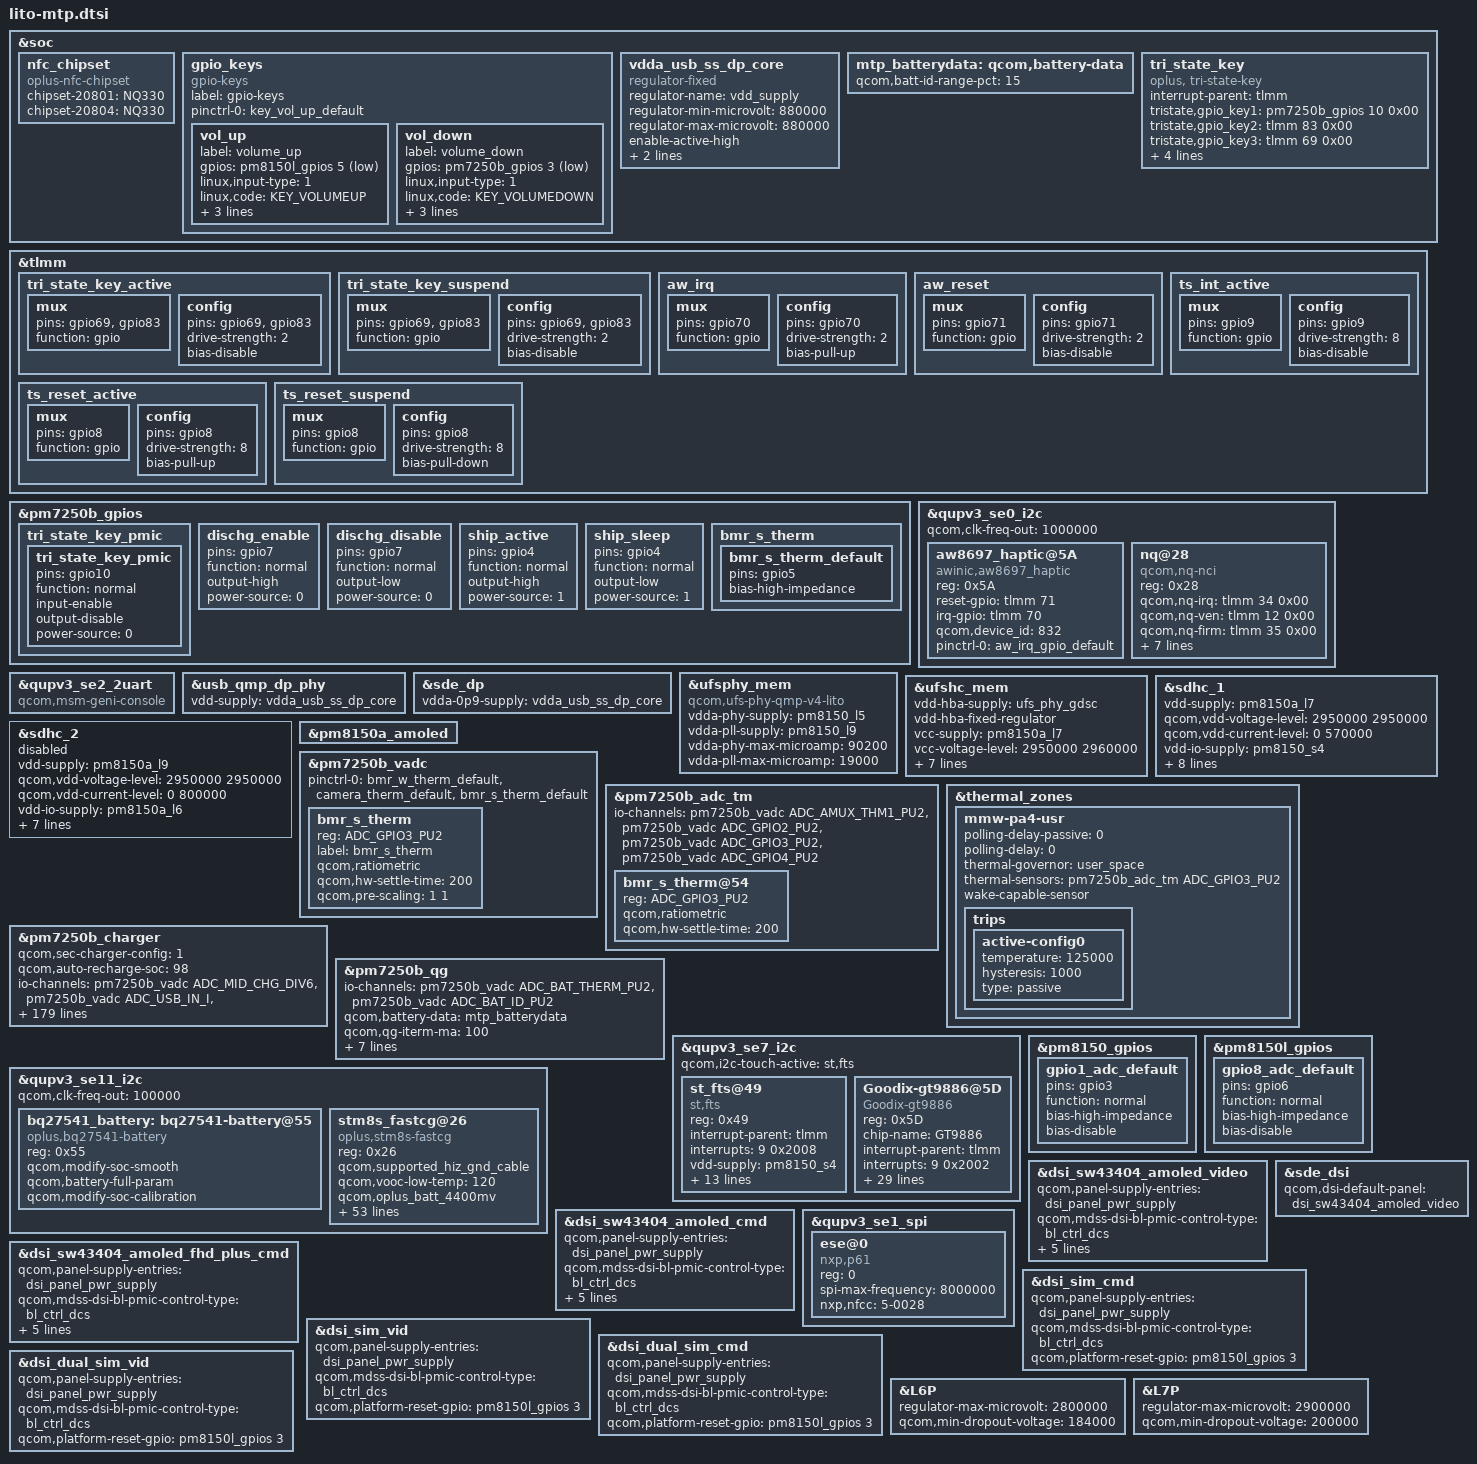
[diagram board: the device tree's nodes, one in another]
#include <dt-bindings/gpio/gpio.h>
#include "lito-audio-overlay.dtsi"
#include "lito-pmic-overlay.dtsi"
#include "lito-sde-display.dtsi"
#include "lito-thermal-overlay.dtsi"
#include "lito-20801-sensor.dtsi"

&soc {
    //add for nfc_chipset
	nfc_chipset {
		compatible = "oplus-nfc-chipset";
		chipset-20801 = "NQ330";
		chipset-20804 = "NQ330";
	};
	gpio_keys {
		compatible = "gpio-keys";
		label = "gpio-keys";

		pinctrl-names = "default";
		pinctrl-0 = <&key_vol_up_default>;

		vol_up {
			label = "volume_up";
			gpios = <&pm8150l_gpios 5 GPIO_ACTIVE_LOW>;
			linux,input-type = <1>;
			linux,code = <KEY_VOLUMEUP>;
			gpio-key,wakeup;
			debounce-interval = <15>;
			linux,can-disable;
		};

               vol_down {
                        label = "volume_down";
                        gpios = <&pm7250b_gpios  3 GPIO_ACTIVE_LOW>;
                        linux,input-type = <1>;
                        linux,code = <KEY_VOLUMEDOWN>;
                        gpio-key,wakeup;
                        debounce-interval = <15>;
                        linux,can-disable;
                };

	};

	vdda_usb_ss_dp_core: vdda_usb_ss_dp_core {
		compatible = "regulator-fixed";
		regulator-name = "vdd_supply";
		regulator-min-microvolt = <880000>;
		regulator-max-microvolt = <880000>;
		enable-active-high;
		gpio = <&pm8150l_gpios 12 GPIO_ACTIVE_HIGH>;
		pinctrl-names = "default";
		pinctrl-0 = <&usb_eldo13>;
	};

	mtp_batterydata: qcom,battery-data {
		qcom,batt-id-range-pct = <15>;
		#include "qg-batterydata-alium-3600mah.dtsi"
		#include "qg-batterydata-atl466271_3300mAh.dtsi"
	};
	
	tri_state_key:tri_state_key {
		compatible = "oplus, tri-state-key";
		status = "ok";
		interrupt-parent = <&tlmm>;
		tristate,gpio_key1 = <&pm7250b_gpios 10 0x00>;
		tristate,gpio_key2 = <&tlmm 83 0x00>;
		tristate,gpio_key3 = <&tlmm 69 0x00>;
		pinctrl-names =
					"pmx_tri_state_key_active",
					"pmx_tri_state_key_suspend";
		pinctrl-0 = <&tri_state_key_active &tri_state_key_pmic>;
		pinctrl-1 = <&tri_state_key_suspend &tri_state_key_pmic>;
	};
};


&tlmm{
	tri_state_key_active: tri_state_key_active {
		mux {
			pins = "gpio69", "gpio83";
			function = "gpio";
		};
		config {
			pins = "gpio69", "gpio83";
			drive-strength = <2>;
			bias-disable;
		};
	};

	tri_state_key_suspend: tri_state_key_suspend {
		mux {
			pins = "gpio69", "gpio83";
			function = "gpio";
		};
		config {
			pins = "gpio69", "gpio83";
			drive-strength = <2>;
			bias-disable;
		};
	};
};

&pm7250b_gpios {
	tri_state_key_pmic {
		tri_state_key_pmic: tri_state_key_pmic {
			pins = "gpio10";
			function = "normal";
			input-enable;
			output-disable;
			power-source = <0>;
		};
	};

        dischg_enable: dischg_enable {
                        pins = "gpio7";
                        function = "normal";
                        output-high;
                        power-source = <0>;
        };

        dischg_disable: dischg_disable {
                        pins = "gpio7";
                        function = "normal";
                        output-low;
                        power-source = <0>;
        };

        ship_active: ship_active {
                        pins = "gpio4";
                        function = "normal";
                        output-high;
                        power-source = <1>;     /* 1.8V input supply */
        };

        ship_sleep: ship_sleep {
                        pins = "gpio4";
                        function = "normal";
                        output-low;
                        power-source = <1>;     /* 1.8V input supply */
        };
};


/*for aw haptic start*/

&tlmm {
       aw_irq: aw_irq {
       mux {
            pins = "gpio70";
            function = "gpio";
       };
       config {
               pins = "gpio70";
               drive-strength = <2>;
               bias-pull-up;
       };
    };
    aw_reset: aw_reset {
       mux {
	            pins = "gpio71";
	            function = "gpio";
	       };
	      config {
	              pins = "gpio71";
	              drive-strength = <2>;
	              bias-disable;
	      };
      };
};
&qupv3_se0_i2c {
	status = "ok";
	aw8697_haptic@5A {
		compatible = "awinic,aw8697_haptic";
		reg = <0x5A>;
		reset-gpio = <&tlmm 71 0x00>;
		irq-gpio = <&tlmm 70 0x00>;
		pinctrl-names = "default";
		qcom,device_id = <832>;

		pinctrl-0 = <&aw_irq_gpio_default>;
		status = "okay";
	};
};

&qupv3_se2_2uart {
    compatible = "qcom,msm-geni-console";
};

&usb_qmp_dp_phy {
	vdd-supply = <&vdda_usb_ss_dp_core>;
};

&sde_dp {
	vdda-0p9-supply = <&vdda_usb_ss_dp_core>;
};

&ufsphy_mem {
	compatible = "qcom,ufs-phy-qmp-v4-lito";

	vdda-phy-supply = <&pm8150_l5>;
	vdda-pll-supply = <&pm8150_l9>;
	vdda-phy-max-microamp = <90200>;
	vdda-pll-max-microamp = <19000>;

	status = "ok";
};

&ufshc_mem {
	vdd-hba-supply = <&ufs_phy_gdsc>;
	vdd-hba-fixed-regulator;
	vcc-supply = <&pm8150a_l7>;
	vcc-voltage-level = <2950000 2960000>;
	vccq2-supply = <&pm8150_s4>;
	vcc-max-microamp = <800000>;
	vccq2-max-microamp = <800000>;

	qcom,vddp-ref-clk-supply = <&pm8150_l9>;
	qcom,vddp-ref-clk-max-microamp = <100>;
	qcom,vddp-ref-clk-min-uV = <1152000>;
	qcom,vddp-ref-clk-max-uV = <1200000>;
	status = "ok";
};

&sdhc_1 {
	vdd-supply = <&pm8150a_l7>;
	qcom,vdd-voltage-level = <2950000 2950000>;
	qcom,vdd-current-level = <0 570000>;

	vdd-io-supply = <&pm8150_s4>;
	qcom,vdd-io-always-on;
	qcom,vdd-io-lpm-sup;
	qcom,vdd-io-voltage-level = <1800000 1800000>;
	qcom,vdd-io-current-level = <0 325000>;

	pinctrl-names = "active", "sleep";
	pinctrl-0 = <&sdc1_clk_on &sdc1_cmd_on &sdc1_data_on
					&sdc1_rclk_on>;
	pinctrl-1 = <&sdc1_clk_off &sdc1_cmd_off &sdc1_data_off
					&sdc1_rclk_off>;

	status = "ok";
};

&sdhc_2 {
	vdd-supply = <&pm8150a_l9>;
	qcom,vdd-voltage-level = <2950000 2950000>;
	qcom,vdd-current-level = <0 800000>;

	vdd-io-supply = <&pm8150a_l6>;
	qcom,vdd-io-voltage-level = <1800000 2950000>;
	qcom,vdd-io-current-level = <0 22000>;

	pinctrl-names = "active", "sleep";
	pinctrl-0 = <&sdc2_clk_on  &sdc2_cmd_on &sdc2_data_on &sdc2_cd_on>;
	pinctrl-1 = <&sdc2_clk_off &sdc2_cmd_off &sdc2_data_off &sdc2_cd_off>;

	cd-gpios = <&tlmm 69 GPIO_ACTIVE_LOW>;

	status = "disabled";
};

&pm8150a_amoled {
	status = "ok";
};

&pm7250b_vadc {
	pinctrl-0 = <
		&bmr_w_therm_default
		&camera_therm_default
		&bmr_s_therm_default
	>;

	bmr_s_therm {
		reg = <ADC_GPIO3_PU2>;
		label = "bmr_s_therm";
		qcom,ratiometric;
		qcom,hw-settle-time = <200>;
		qcom,pre-scaling = <1 1>;
	};
};

&pm7250b_gpios {
	bmr_s_therm {
		bmr_s_therm_default: bmr_s_therm_default {
			pins = "gpio5";
			bias-high-impedance;
		};
	};
};

&pm7250b_adc_tm {
	io-channels = <&pm7250b_vadc ADC_AMUX_THM1_PU2>,
			<&pm7250b_vadc ADC_GPIO2_PU2>,
			<&pm7250b_vadc ADC_GPIO3_PU2>,
			<&pm7250b_vadc ADC_GPIO4_PU2>;

	bmr_s_therm@54 {
		reg = <ADC_GPIO3_PU2>;
		qcom,ratiometric;
		qcom,hw-settle-time = <200>;
	};
};

&thermal_zones {
	mmw-pa4-usr {
		polling-delay-passive = <0>;
		polling-delay = <0>;
		thermal-governor = "user_space";
		thermal-sensors = <&pm7250b_adc_tm ADC_GPIO3_PU2>;
		wake-capable-sensor;
		trips {
			active-config0 {
				temperature = <125000>;
				hysteresis = <1000>;
				type = "passive";
			};
		};
	};
};

&pm7250b_charger {
        status = "ok";
        qcom,sec-charger-config = <1>;
        qcom,auto-recharge-soc = <98>;
        io-channels = <&pm7250b_vadc ADC_MID_CHG_DIV6>,
                      <&pm7250b_vadc ADC_USB_IN_I>,
                      <&pm7250b_vadc ADC_SBUx>,
                      <&pm7250b_vadc ADC_VPH_PWR>,
		      <&pm7250b_vadc ADC_CHG_TEMP>,
		      <&pm7250b_vadc ADC_DIE_TEMP>,
		      <&pm7250b_vadc ADC_AMUX_THM3_PU2>,
                      <&pm7250b_vadc ADC_USB_IN_V_16>,
		      <&pm8150l_vadc ADC_GPIO3_PU2>,
 		      <&pm8150_vadc ADC_GPIO1_PU1>,
 		      <&pm8150l_vadc ADC_GPIO2_PU1>;

        io-channel-names = "mid_voltage",
                           "usb_in_current",
                           "sbux_res",
                           "vph_voltage",
                           "chg_temp",
                           "die_temp",
                           "conn_temp",
                           "usb_in_voltage",
			   "skin_therm",
                           "usb_temp_l",
                           "usb_temp_r";

        qcom,battery-data = <&mtp_batterydata>;
        //qcom,step-charging-enable;
        //qcom,sw-jeita-enable;
        //qcom,wd-bark-time-secs = <16>;
        //qcom,suspend-input-on-debug-batt;
        //qcom,fcc-stepping-enable;
        qcom,smb-internal-pull-kohm = <0>;
        op,low-voltage-charger;
};



/*&pm7250b_charger {
	status = "ok";
	io-channels = <&pm7250b_vadc ADC_USB_IN_V_16>,
		      <&pm7250b_vadc ADC_USB_IN_I>,
		      <&pm7250b_vadc ADC_CHG_TEMP>,
		      <&pm7250b_vadc ADC_DIE_TEMP>,
		      <&pm7250b_vadc ADC_AMUX_THM3_PU2>,
		      <&pm7250b_vadc ADC_SBUx>,
		      <&pm7250b_vadc ADC_VPH_PWR>,
		      <&pm7250b_vadc ADC_AMUX_THM1_PU2>;
	io-channel-names = "usb_in_voltage",
			   "usb_in_current",
			   "chg_temp",
			   "die_temp",
			   "conn_temp",
			   "sbux_res",
			   "vph_voltage",
			   "skin_temp";
	qcom,battery-data = <&mtp_batterydata>;
	qcom,sec-charger-config = <1>;
	qcom,auto-recharge-soc = <98>;
	qcom,step-charging-enable;
	qcom,sw-jeita-enable;
	qcom,charger-temp-max = <800>;
	qcom,smb-temp-max = <800>;
	qcom,suspend-input-on-debug-batt;
	qcom,fcc-stepping-enable;
	qcom,fcc-step-delay-ms = <100>;
	qcom,fcc-step-size-ua = <100000>;
	qcom,smb-internal-pull-kohm = <0>;
	qcom,en-skin-therm-mitigation;
	qcom,hvdcp3-standalone-config;
};
*/

&pm7250b_qg {
	status = "ok";
	io-channels = <&pm7250b_vadc ADC_BAT_THERM_PU2>,
		      <&pm7250b_vadc ADC_BAT_ID_PU2>;
	io-channel-names = "batt-therm",
			   "batt-id";
	qcom,battery-data = <&mtp_batterydata>;
	qcom,qg-iterm-ma = <100>;
	qcom,hold-soc-while-full;
	qcom,linearize-soc;
	qcom,cl-feedback-on;
	qcom,tcss-enable;
	qcom,fvss-enable;
	qcom,fvss-vbatt-mv = <3300>;
	qcom,bass-enable;
};

&qupv3_se7_i2c {
	#address-cells = <1>;
	#size-cells = <0>;

	status = "ok";
	qcom,i2c-touch-active = "st,fts";

	st_fts@49 {
		compatible = "st,fts";
		reg = <0x49>;
		interrupt-parent = <&tlmm>;
		interrupts = <9 0x2008>;
		vdd-supply = <&pm8150_s4>;
		avdd-supply = <&pm8150_l13>;
		pinctrl-names = "pmx_ts_active", "pmx_ts_suspend";
		pinctrl-0 = <&ts_active>;
		pinctrl-1 = <&ts_int_suspend &ts_reset_suspend>;
		st,irq-gpio = <&tlmm 9 0x2008>;
		st,reset-gpio = <&tlmm 8 0x00>;
		st,regulator_dvdd = "vdd";
		st,regulator_avdd = "avdd";
		st,x-flip = <1>;
		st,y-flip = <1>;
		st,power_on_suspend;
		panel = <&dsi_sw43404_amoled_cmd &dsi_sw43404_amoled_video
			 &dsi_sw43404_amoled_fhd_plus_cmd>;
	};
};

&qupv3_se7_i2c {
        status = "ok";
        Goodix-gt9886@5D {
                compatible = "Goodix-gt9886";
                reg = <0x5D>;
                chip-name = "GT9886";

                /* Interrupt && Irq-gpio */
                interrupt-parent = <&tlmm>;
                interrupts = <9 0x2002>;

                /* Power Config */
                vdd_2v8-supply = <&pm8150_l13>;
                vdd_2v8_volt = <3008000>;
		enable1v8_gpio = <&pm8150l_gpios 1 GPIO_ACTIVE_LOW>;

               	/* Other HW Resource */
                irq-gpio = <&tlmm 9 0x2002>;
                reset-gpio = <&tlmm 8 0x1>;
                pinctrl-names = "pin_set_high", "pin_set_low";
                pinctrl-0 = <&ts_int_active &ts_reset_active>;
                pinctrl-1 = <&ts_reset_suspend>;

                touchpanel,max-num-support = <10>;
                touchpanel,tx-rx-num = <15 34>;
                touchpanel,panel-coords = <1080 2400>;
                touchpanel,display-coords = <1080 2400>;

		tp_type = <8>;
		platform_support_project = <20801 20804>;
                platform_support_project_dir = <20801 20801>;
                platform_support_project_commandline = "default_commandline", "default_commandline";

                /* SW Support Feature Control */
                black_gesture_support;
                game_switch_support;
                fw_edge_limit_support;
		pressure_report_support;
		charger_pump_support;
		smart_gesture_support;
                fw_update_app_support;
                fingerprint_underscreen_support;
                esd_handle_support;
		register-is-16bit;

				/*
                 *Virtual Key Config:
                 *1:touchpanel,button-type: <virtualkey_type  supportted_button-map>
                 *virtualkey_type:
                 *Type 1: using board_properties
                 *Type 2: using same IC (button zone&& touch zone are seprate)
                 *Type 3: using diffrent IC (button zone&& touch zone are seprate)
                 *Type 4: No need of virtual key process
                 *supportted_button-map:select|menu|home|back
                 *
                 *2:touchpanel,button-map
                 *type (X1,Y1)(X2,Y2)(X3,Y3)(Width_X,Hight_Y)--Only when button-type is 0
                 */
                touchpanel,button-type = <4>;
                touchpanel.button-TRx = <0 0>;

	};
};

&qupv3_se11_i2c {
        status = "ok";
        qcom,clk-freq-out = <100000>;
        bq27541_battery:bq27541-battery@55 {
                status = "ok";
                compatible = "oplus,bq27541-battery";
                reg = <0x55>;
                qcom,modify-soc-smooth;
                qcom,battery-full-param;//only for wite battery full param in guage dirver probe on 7250 platform
                qcom,modify-soc-calibration;
        };

        stm8s_fastcg@26{
                status = "okay";
                compatible = "oplus,stm8s-fastcg";
                reg = <0x26>;
		qcom,supported_hiz_gnd_cable;

                qcom,vooc-low-temp = <120>;
		qcom,oplus_batt_4400mv;
                qcom,vooc_fw_update_newmethod;
                qcom,vooc-high-temp = <480>;
                qcom,vooc-low-soc = <1>;
                qcom,vooc-high-soc = <90>;
                qcom,vooc-fw-type = <0x27>;
                qcom,vooc-max-input-current-support = <6000>;
                qcom,vooc-max-input-volt-support = <5000>;

                qcom,vooc_multistep_adjust_current_support;
                qcom,vooc_multistep_initial_batt_temp = <360>;
                qcom,vooc_strategy_normal_current = <0x06>;
                qcom,vooc-normal-to-little-cool-current = <0x05>;
                qcom,vooc_batt_over_high_temp = <440>;
                qcom,vooc_batt_over_low_temp = <45>;
                qcom,vooc_over_high_or_low_current = <0x0>;

                qcom,vooc_strategy1_batt_high_temp0 = <425>;
                qcom,vooc_strategy1_batt_high_temp1 = <450>;
                qcom,vooc_strategy1_batt_high_temp2 = <480>;
                qcom,vooc_strategy1_batt_low_temp2 = <420>;
                qcom,vooc_strategy1_batt_low_temp1 = <415>;
                qcom,vooc_strategy1_batt_low_temp0 = <400>;

                qcom,vooc_strategy1_high_current0 = <0x05>;//5A
                qcom,vooc_strategy1_high_current1 = <0x04>;//4A
                qcom,vooc_strategy1_high_current2 = <0x02>;//2A
                qcom,vooc_strategy1_low_current2 = <0x06>;//6A
                qcom,vooc_strategy1_low_current1 = <0x06>;//6A
                qcom,vooc_strategy1_low_current0 = <0x06>;//6A

                qcom,vooc_strategy2_batt_up_temp1 = <375>;
                qcom,vooc_strategy2_batt_up_down_temp2 = <380>;
                qcom,vooc_strategy2_batt_up_temp3 = <390>;
                qcom,vooc_strategy2_batt_up_down_temp4 = <400>;
                qcom,vooc_strategy2_batt_up_temp5 = <410>;
                qcom,vooc_strategy2_batt_up_temp6 = <415>;
                qcom,vooc_strategy2_high0_current = <0x06>;
                qcom,vooc_strategy2_high1_current = <0x06>;
                qcom,vooc_strategy2_high2_current = <0x06>;
                qcom,vooc_strategy2_high3_current = <0x06>;


                pinctrl-names = "switch1_act_switch2_act", "switch1_sleep_switch2_sleep",
                                                "switch1_act_switch3_act", "switch1_sleep_switch3_sleep",
                                                "switch1_act_switch2_sleep", "switch1_sleep_switch2_act",
                                                "clock_active","clock_sleep",
                                                "data_active","data_sleep",
                                                "reset_active","reset_sleep";
                pinctrl-0 = <&charging_switch1_active>;
                pinctrl-1 = <&charging_switch1_sleep>;
                pinctrl-2 = <&charging_switch1_active>;
                pinctrl-3 = <&charging_switch1_sleep>;
                pinctrl-4 = <&charging_switch1_active>;
                pinctrl-5 = <&charging_switch1_sleep>;
                pinctrl-6 = <&charging_clock_active>;
                pinctrl-7 = <&charging_clock_sleep>;
                pinctrl-8 = <&charging_data_active>;
                pinctrl-9 = <&charging_data_sleep>;
                pinctrl-10 = <&charging_reset_active>;
                pinctrl-11 = <&charging_reset_sleep>;

                qcom,charging_switch1-gpio = <&tlmm 4 0x00>;
		qcom,charging_switch1_ctr1-gpio = <&tlmm 126 0x00>;
                //qcom,charging_switch2-gpio = <&tlmm 113 0x00>;
                //qcom,charging_switch3-gpio = <&tlmm 126 0x00>;

                qcom,charging_reset-gpio = <&tlmm 24 0x00>;
                qcom,charging_clock-gpio = <&tlmm 44 0x00>;
                qcom,charging_data-gpio = <&tlmm 45 0x00>;
        };
};

&pm8150_gpios {
	gpio1_adc_default: gpio1_adc_default {
			   pins = "gpio3"; /* GPIO3 */
			   function = "normal"; /* normal */
			   bias-high-impedance; /* DISABLE GPIO03 for ADC*/
			   bias-disable;
	};
};

&pm8150l_gpios {
	gpio8_adc_default: gpio8_adc_default {
			   pins = "gpio6"; /* GPIO6 */
			   function = "normal"; /* normal */
			   bias-high-impedance; /* DISABLE GPIO03 for ADC*/
			   bias-disable;
	};
};

&pm7250b_charger {
                        //for smb5:
                        qcom,usb-icl-ua = <1800000>;
                        qcom,fcc-max-ua = <2000000>;
                        qcom,fv-max-uv = <4365000>;
                        qcom,qc3-disable;
                        qcom,hvdcp-disable;
                        //io-channels = <&pm8150b_vadc ADC_GPIO3>;
                        //io-channel-names = "chgID_voltage_adc";
                        //qcom,otg-cl-ua = <2000000>;
                        qcom,float-option = <1>;
                        qcom,oplus-pps-usbpd-detection = <&pm7250b_pdphy>;

                        //for oplus chg framework:
                        qcom,skip_usbtemp_cool_down;
                        qcom,input_current_charger_ma = <6000>;
                        qcom,pd_input_current_charger_ma = <3000>;
                        qcom,qc_input_current_charger_ma = <2000>;

                        qcom,input_current_usb_ma = <500>;

                        qcom,input_current_cdp_ma = <1500>;
                        qcom,input_current_led_ma = <1200>;
                        qcom,input_current_led_ma_high = <3000>;
                        qcom,input_current_led_ma_warm = <4000>;
                        qcom,input_current_led_ma_normal = <5000>;
                        qcom,led_warm_bat_decidegc = <450>;
                        qcom,led_high_bat_decidegc = <480>;

                        qcom,input_current_camera_ma = <1200>;

                        qcom,input_current_vooc_led_ma_high = <3000>;
                        qcom,input_current_vooc_led_ma_warm = <4000>;
                        qcom,input_current_vooc_led_ma_normal = <5000>;
                        qcom,input_current_vooc_ma_normal = <6000>;
                        qcom,vooc_temp_bat_normal_decidegc = <380>;
                        qcom,input_current_vooc_ma_warm = <5000>;
                        qcom,vooc_temp_bat_warm_decidegc = <450>;
                        qcom,input_current_vooc_ma_high = <3000>;
                        qcom,vooc_temp_bat_hot_decidegc = <480>;

                        qcom,charger_current_vooc_ma_normal = <6000>;

                        qcom,chg_ctrl_by_calling;
                        qcom,input_current_calling_ma = <1500>;

                        //qcom,input_current_led_ma_overtemp = <900>;
                        qcom,overtemp_bat_decidegc = <350>;
                        qcom,iterm_disabled = <0>;
                        qcom,iterm_ma = <230>;
                        qcom,recharge-mv = <100>;
                        qcom,batt_capacity_mah = <4115>;/*typical capacity*/
                        //qcom,batt_capacity_mah = <4170>; /*rated capacity*/

                        qcom,removed_bat_decidegc = <190>;  /*<-19C*/

                        qcom,cold_bat_decidegc = <20>;  /*-2C~0C*/
                        qcom,temp_cold_vfloat_mv = <3980>;
                        qcom,temp_cold_fastchg_current_ma = <300>;

                        qcom,little_cold_bat_decidegc = <0>;    /*0C~5C*/
                        qcom,temp_little_cold_vfloat_mv = <4435>;
                        qcom,temp_little_cold_fastchg_current_ma_high = <4000>;
                        qcom,temp_little_cold_fastchg_current_ma_low = <3500>;
                        qcom,temp_little_cold_fastchg_current_ma = <3500>;
                        qcom,pd_temp_little_cold_fastchg_current_ma_high = <1850>;
                        qcom,pd_temp_little_cold_fastchg_current_ma_low = <1100>;
                        qcom,qc_temp_little_cold_fastchg_current_ma_high = <1200>;
                        qcom,qc_temp_little_cold_fastchg_current_ma_low = <950>;

                        qcom,cool_bat_decidegc = <50>;  /*5C~12C*/
                        qcom,temp_cool_vfloat_mv = <4435>;
                        qcom,temp_cool_fastchg_current_ma_high = <4500>;
                        qcom,temp_cool_fastchg_current_ma_low = <4000>;
                        qcom,pd_temp_cool_fastchg_current_ma_high = <2600>;
                        qcom,pd_temp_cool_fastchg_current_ma_low = <1850>;
                        qcom,qc_temp_cool_fastchg_current_ma_high = <1800>;
                        qcom,qc_temp_cool_fastchg_current_ma_low = <1200>;

                        qcom,little_cool_bat_decidegc = <120>;  /*12C~16C*/
                        qcom,temp_little_cool_vfloat_mv = <4435>;
                        qcom,temp_little_cool_fastchg_current_ma = <5000>;
                        qcom,pd_temp_little_cool_fastchg_current_ma = <3000>;
                        qcom,qc_temp_little_cool_fastchg_current_ma = <2000>;

                        qcom,normal_bat_decidegc = <160>;       /*16C~44C*/
                        qcom,temp_normal_fastchg_current_ma = <6000>;
                        qcom,temp_normal_vfloat_mv = <4435>;
                        qcom,pd_temp_normal_fastchg_current_ma = <3000>;
                        qcom,qc_temp_normal_fastchg_current_ma = <2000>;


                        qcom,warm_bat_decidegc = <480>;         /*45C~53C*/ /*8pin Bat Vooc project need add 3 degree C*/
                        qcom,temp_warm_vfloat_mv = <4130>;
                        qcom,temp_warm_fastchg_current_ma = <5000>;
                        qcom,pd_temp_warm_fastchg_current_ma = <1100>;
                        qcom,qc_temp_warm_fastchg_current_ma = <1100>;
                        qcom,temp_warm_fastchg_current_ma_led_on = <4000>;

                        qcom,hot_bat_decidegc = <500>;

                        qcom,non_standard_vfloat_mv = <3980>;
                        qcom,non_standard_fastchg_current_ma = <2000>;

                        //qcom,short_c_bat_cv_mv = <4330>;
                        //qcom,short_c_bat_vfloat_mv = <3800>;
                        //qcom,short_c_bat_fastchg_current_ma = <512>;

                        qcom,cold_vfloat_sw_limit = <3980>;
                        qcom,little_cold_vfloat_sw_limit = <4385>;
                        qcom,cool_vfloat_sw_limit = <4385>;
                        qcom,little_cool_vfloat_sw_limit = <4385>;
                        qcom,normal_vfloat_sw_limit = <4385>;
                        qcom,warm_vfloat_sw_limit = <4080>;
                        qcom,non_standard_vfloat_sw_limit = <3930>;
                        qcom,short_c_bat_vfloat_sw_limit = <3750>;


                        qcom,max_chg_time_sec = <36000>;
                        qcom,charger_hv_thr = <5900>;
                        qcom,charger_recv_thr = <5500>;
                        qcom,charger_lv_thr = <3400>;
                        qcom,vbatt_full_thr = <4475>;
                        qcom,vbatt_hv_thr = <4550>;
                        qcom,vfloat_step_mv = <8>;
                        qcom,non_standard_vfloat_over_sw_limit = <3990>;
                        qcom,cold_vfloat_over_sw_limit = <3990>;
                        qcom,little_cold_vfloat_over_sw_limit = <4445>;
                        qcom,cool_vfloat_over_sw_limit = <4445>;
                        qcom,little_cool_vfloat_over_sw_limit = <4445>;
                        qcom,normal_vfloat_over_sw_limit = <4445>;
                        qcom,warm_vfloat_over_sw_limit = <4140>;

                        qcom,vbatt_power_off = <3250>;
                        qcom,vbatt_soc_1 = <3310>;
                        qcom,vooc_project = <1>;
                        qcom,vbatt_num = <1>;
                        //qcom,ffc_support;
                        recharge_after_full;

                        qcom,normal_vterm_hw_inc = <18>;
                        qcom,non_normal_vterm_hw_inc = <18>;

                        qcom,ff1_normal_fastchg_ma = <1100>;
                        qcom,ff1_warm_fastchg_ma = <1100>;
                        qcom,ffc2_normal_fastchg_ma = <350>;/*12C~35c*/
                        qcom,ffc2_temp_warm_decidegc = <350>;
                        qcom,ffc2_warm_fastchg_ma = <400>;/*35C~40c*/
                        qcom,ffc2_temp_high_decidegc = <400>;
                        qcom,ffc2_temp_low_decidegc = <120>;
                        qcom,ffc2_exit_step_ma = <100>;
                        qcom,ff1_exit_step_ma = <550>;
                        qcom,ff1_warm_exit_step_ma = <650>;

                        qcom,ffc_normal_vfloat_sw_limit = <4455>;
                        qcom,ffc2_normal_vfloat_sw_limit = <4445>;
                        qcom,ffc2_warm_vfloat_sw_limit = <4445>;
                        qcom,ffc_temp_normal_vfloat_mv = <4475>;
                        qcom,ffc1_temp_normal_vfloat_mv = <4475>;
                        qcom,ffc2_temp_normal_vfloat_mv = <4500>;
                        qcom,ffc_normal_vfloat_over_sw_limit = <4475>;
                        qcom,ffc1_normal_vfloat_over_sw_limit = <4475>;
                        qcom,ffc2_normal_vfloat_over_sw_limit = <4500>;

                        qcom,default_iterm_ma = <310>;
                        qcom,default_temp_normal_fastchg_current_ma = <2200>;
                        qcom,default_normal_vfloat_sw_limit = <4385>;
                        qcom,default_temp_normal_vfloat_mv = <4435>;
                        qcom,default_normal_vfloat_over_sw_limit = <4445>;

                        qcom,default_temp_little_cool_fastchg_current_ma = <2200>;
                        qcom,default_little_cool_vfloat_sw_limit = <4385>;
                        qcom,default_temp_little_cool_vfloat_mv = <4435>;
                        qcom,default_little_cool_vfloat_over_sw_limit = <4445>;

                        ///qcom,offset_temp = <30>;
                        //for control:
                        //qcom,suspend_after_full;
                        qcom,check_batt_full_by_sw;
                        qcom,external_gauge;
                        qcom,chg_ctrl_by_lcd;
                        qcom,chg_ctrl_by_vooc;
                        qcom,chg_ctrl_by_camera;
                        qcom,sw_vfloat_over_protect_enable;
                        qcom,lpd-disable;

                        //for PD9V or QC9V
                        qcom,vbatt_pdqc_to_5v_thr = <4180>;

                        //qcom,vooc_show_ui_soc_decimal;
                        //qcom,ui_soc_decimal_speedmin = <20>;//2A

                        qcom,chargerid_switch-gpio = <&tlmm 50 0x00>;
                        qcom,ship-gpio = <&pm7250b_gpios 4 0x00>;
                        qcom,ccdetect-gpio = <&tlmm 68 0x00>;
                        //qcom,shortc-gpio = <&tlmm 43 0x00>;
                        qcom,dischg-gpio = <&pm7250b_gpios 7 0x00>;
                        //qcom,charger_int-gpio = <&tlmm 15 0x00>;
                        //qcom,input_pg-gpio = <&tlmm 6 0x00>;
                        //qcom,charger_error-gpio = <&tlmm 118 0x00>;

                        pinctrl-names = "ccdetect_active",
					"ccdetect_sleep",
					"dischg_enable",
					"dischg_disable",
					"ship_active",
					"ship_sleep",
					"gpio1_adc_default",
					"gpio8_adc_default";

                        pinctrl-0 = <&ccdetect_active>;
                        pinctrl-1 = <&ccdetect_sleep>;
                        pinctrl-2 = <&dischg_enable>;
                        pinctrl-3 = <&dischg_disable>;
                        pinctrl-4 = <&ship_active>;
                        pinctrl-5 = <&ship_sleep>;
                        pinctrl-6 = <&gpio1_adc_default>;
                        pinctrl-7 = <&gpio8_adc_default>;
                        //pinctrl-12 = <&gpio5_adc_default>; // aboard - TODO
};

&tlmm {
	ts_int_active: ts_int_active {
		mux {
			pins = "gpio9";
			function = "gpio";
		};
		config {
			pins = "gpio9";
			drive-strength = <8>;
			bias-disable;
		};
	};
	ts_reset_active: ts_reset_active {
		mux {
			pins = "gpio8";
			function = "gpio";
		};
		config {
			pins = "gpio8";
			drive-strength = <8>;
			bias-pull-up;
		};
	};
	ts_reset_suspend: ts_reset_suspend {
		mux {
			pins = "gpio8";
			function = "gpio";
		};
		config {
			pins = "gpio8";
			drive-strength = <8>;
			bias-pull-down;
		};
	};
};

&dsi_sw43404_amoled_video {
	qcom,panel-supply-entries = <&dsi_panel_pwr_supply>;
	qcom,mdss-dsi-bl-pmic-control-type = "bl_ctrl_dcs";
	qcom,mdss-dsi-bl-min-level = <1>;
	qcom,mdss-dsi-bl-max-level = <1023>;
	qcom,mdss-brightness-max-level = <255>;
	qcom,platform-te-gpio = <&tlmm 10 0>;
	qcom,platform-reset-gpio = <&pm8150l_gpios 3 0>;
};

&dsi_sw43404_amoled_cmd {
	qcom,panel-supply-entries = <&dsi_panel_pwr_supply>;
	qcom,mdss-dsi-bl-pmic-control-type = "bl_ctrl_dcs";
	qcom,mdss-dsi-bl-min-level = <1>;
	qcom,mdss-dsi-bl-max-level = <1023>;
	qcom,mdss-brightness-max-level = <255>;
	qcom,platform-te-gpio = <&tlmm 10 0>;
	qcom,platform-reset-gpio = <&pm8150l_gpios 3 0>;
};

&dsi_sw43404_amoled_fhd_plus_cmd {
	qcom,panel-supply-entries = <&dsi_panel_pwr_supply>;
	qcom,mdss-dsi-bl-pmic-control-type = "bl_ctrl_dcs";
	qcom,mdss-dsi-bl-min-level = <1>;
	qcom,mdss-dsi-bl-max-level = <1023>;
	qcom,mdss-brightness-max-level = <255>;
	qcom,platform-te-gpio = <&tlmm 10 0>;
	qcom,platform-reset-gpio = <&pm8150l_gpios 3 0>;
};

&sde_dsi {
	qcom,dsi-default-panel = <&dsi_sw43404_amoled_video>;
};

/* Add for NXP NFCC */
&qupv3_se0_i2c {
        status = "ok";
        qcom,clk-freq-out = <1000000>;
        #address-cells = <1>;
        #size-cells = <0>;
    nq@28 {
        compatible = "qcom,nq-nci";
        reg = <0x28>;
        qcom,nq-irq = <&tlmm 34 0x00>;
        qcom,nq-ven = <&tlmm 12 0x00>;
        qcom,nq-firm = <&tlmm 35 0x00>;
        qcom,nq-clkreq = <&tlmm 31 0x00>;
        interrupt-parent = <&tlmm>;
        interrupts = <34 0>;
        interrupt-names = "nfc_irq";
        pinctrl-names = "nfc_active", "nfc_suspend";
        pinctrl-0 = <&nfc_int_active &nfc_enable_active
                        &nfc_clk_req_active>;
        pinctrl-1 = <&nfc_int_suspend &nfc_enable_suspend
                        &nfc_clk_req_suspend>;
    };
};

/* Add for NXP eSE */
&qupv3_se1_spi {
    status = "ok";
        //qcom,disable-autosuspend;

    ese@0 {
        compatible = "nxp,p61";
        reg = <0>;
        spi-max-frequency = <8000000>;
        nxp,nfcc = "5-0028";
    };
};

&dsi_sim_cmd {
	qcom,panel-supply-entries = <&dsi_panel_pwr_supply>;
	qcom,mdss-dsi-bl-pmic-control-type = "bl_ctrl_dcs";
	qcom,platform-reset-gpio = <&pm8150l_gpios 3 0>;
};

&dsi_sim_vid {
	qcom,panel-supply-entries = <&dsi_panel_pwr_supply>;
	qcom,mdss-dsi-bl-pmic-control-type = "bl_ctrl_dcs";
	qcom,platform-reset-gpio = <&pm8150l_gpios 3 0>;
};

&dsi_dual_sim_cmd {
	qcom,panel-supply-entries = <&dsi_panel_pwr_supply>;
	qcom,mdss-dsi-bl-pmic-control-type = "bl_ctrl_dcs";
	qcom,platform-reset-gpio = <&pm8150l_gpios 3 0>;
};

&dsi_dual_sim_vid {
	qcom,panel-supply-entries = <&dsi_panel_pwr_supply>;
	qcom,mdss-dsi-bl-pmic-control-type = "bl_ctrl_dcs";
	qcom,platform-reset-gpio = <&pm8150l_gpios 3 0>;
};


&L6P {
	regulator-max-microvolt = <2800000>;
	/* Reduced the headroom by 16mV for AHC */
	qcom,min-dropout-voltage = <184000>;
};

&L7P {
	regulator-max-microvolt = <2900000>;
	/* Reduced the headroom by 16mV for AHC */
	qcom,min-dropout-voltage = <200000>;
};
